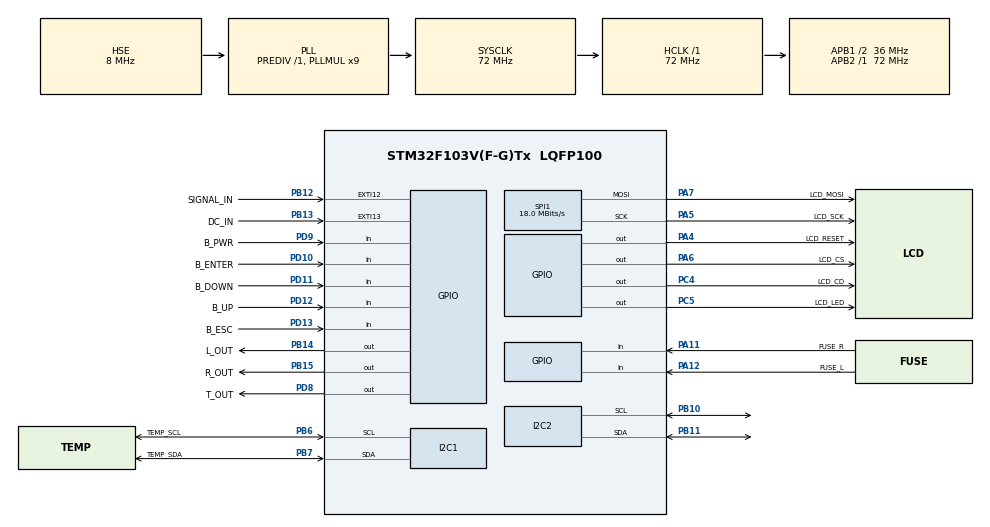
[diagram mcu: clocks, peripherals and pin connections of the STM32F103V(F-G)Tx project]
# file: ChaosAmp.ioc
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Mcu.Family=STM32F1
Mcu.Name=STM32F103V(F-G)Tx
Mcu.Package=LQFP100
NVIC.EXTI15_10_IRQn=true\:0\:0\:false\:false\:true\:true\:true
NVIC.PriorityGroup=NVIC_PRIORITYGROUP_4
OSC_IN.Mode=HSE-External-Oscillator
OSC_IN.Signal=RCC_OSC_IN
OSC_OUT.Mode=HSE-External-Oscillator
OSC_OUT.Signal=RCC_OSC_OUT
PA11.GPIO_Label=FUSE_R
PA11.GPIO_PuPd=GPIO_PULLDOWN
PA11.Signal=GPIO_Input
PA12.GPIO_Label=FUSE_L
PA12.GPIO_PuPd=GPIO_PULLDOWN
PA12.Signal=GPIO_Input
PA13.Mode=Serial_Wire
PA13.Signal=SYS_JTMS-SWDIO
PA14.Mode=Serial_Wire
PA14.Signal=SYS_JTCK-SWCLK
PA4.GPIO_Label=LCD_RESET
PA4.Signal=GPIO_Output
PA5.GPIO_Label=LCD_SCK
PA5.Mode=TX_Only_Simplex_Unidirect_Master
PA5.Signal=SPI1_SCK
PA6.GPIO_Label=LCD_CS
PA6.Signal=GPIO_Output
PA7.GPIO_Label=LCD_MOSI
PA7.Mode=TX_Only_Simplex_Unidirect_Master
PA7.Signal=SPI1_MOSI
PB10.Mode=I2C
PB10.Signal=I2C2_SCL
PB11.Mode=I2C
PB11.Signal=I2C2_SDA
PB12.GPIO_Label=SIGNAL_IN
PB12.GPIO_ModeDefaultEXTI=GPIO_MODE_IT_FALLING
PB12.Signal=GPXTI12
PB13.GPIO_Label=DC_IN
PB13.GPIO_ModeDefaultEXTI=GPIO_MODE_IT_FALLING
PB13.Signal=GPXTI13
PB14.GPIO_Label=L_OUT
PB14.GPIO_PuPd=GPIO_PULLDOWN
PB14.Signal=GPIO_Output
PB15.GPIO_Label=R_OUT
PB15.GPIO_PuPd=GPIO_PULLDOWN
PB15.Signal=GPIO_Output
PB6.GPIO_Label=TEMP_SCL
PB6.Mode=I2C
PB6.Signal=I2C1_SCL
PB7.GPIO_Label=TEMP_SDA
PB7.Mode=I2C
PB7.Signal=I2C1_SDA
PC4.GPIO_Label=LCD_CD
PC4.PinState=GPIO_PIN_RESET
PC4.Signal=GPIO_Output
PC5.GPIO_Label=LCD_LED
PC5.Signal=GPIO_Output
PD10.GPIO_Label=B_ENTER
PD10.GPIO_PuPd=GPIO_PULLUP
PD10.Signal=GPIO_Input
PD11.GPIO_Label=B_DOWN
PD11.GPIO_PuPd=GPIO_PULLUP
PD11.Signal=GPIO_Input
PD12.GPIO_Label=B_UP
PD12.GPIO_PuPd=GPIO_PULLUP
PD12.Signal=GPIO_Input
PD13.GPIO_Label=B_ESC
PD13.GPIO_PuPd=GPIO_PULLUP
PD13.Signal=GPIO_Input
PD8.GPIO_Label=T_OUT
PD8.GPIO_PuPd=GPIO_PULLDOWN
PD8.Signal=GPIO_Output
PD9.GPIO_Label=B_PWR
PD9.GPIO_PuPd=GPIO_PULLUP
PD9.Signal=GPIO_Input
ProjectManager.HeapSize=0x200
ProjectManager.StackSize=0x400
ProjectManager.TargetToolchain=Makefile
RCC.AHBFreq_Value=72000000
RCC.APB1CLKDivider=RCC_HCLK_DIV2
RCC.APB1Freq_Value=36000000
RCC.APB1TimFreq_Value=72000000
RCC.APB2Freq_Value=72000000
RCC.APB2TimFreq_Value=72000000
RCC.HCLKFreq_Value=72000000
RCC.PLLMUL=RCC_PLL_MUL9
RCC.PLLSourceVirtual=RCC_PLLSOURCE_HSE
RCC.SYSCLKFreq_VALUE=72000000
RCC.SYSCLKSource=RCC_SYSCLKSOURCE_PLLCLK
RCC.USBFreq_Value=72000000
SPI1.BaudRatePrescaler=SPI_BAUDRATEPRESCALER_4
SPI1.CalculateBaudRate=18.0 MBits/s
SPI1.Direction=SPI_DIRECTION_2LINES
SPI1.Mode=SPI_MODE_MASTER
SPI1.VirtualType=VM_MASTER
board=custom

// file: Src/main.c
/* USER CODE BEGIN Header */
/**
  ******************************************************************************
  * @file           : main.c
  * @brief          : Main program body
  ******************************************************************************
  * @attention
  *
  * <h2><center>&copy; Copyright (c) 2020 STMicroelectronics.
  * All rights reserved.</center></h2>
  *
  * This software component is licensed by ST under BSD 3-Clause license,
  * the "License"; You may not use this file except in compliance with the
  * License. You may obtain a copy of the License at:
  *                        opensource.org/licenses/BSD-3-Clause
  *
  ******************************************************************************
  */
/* USER CODE END Header */

#include "main.h"

/* USER CODE BEGIN Includes */
#include "AmpIO.h"
/* USER CODE END Includes */

I2C_HandleTypeDef hi2c1;
I2C_HandleTypeDef hi2c2;

SPI_HandleTypeDef hspi1;

void SystemClock_Config(void);
static void MX_GPIO_Init(void);
static void MX_I2C1_Init(void);
static void MX_I2C2_Init(void);
static void MX_SPI1_Init(void);

int main(void)
{

  /* MCU Configuration--------------------------------------------------------*/

  /* Reset of all peripherals, Initializes the Flash interface and the Systick. */
  HAL_Init();

  /* Configure the system clock */
  SystemClock_Config();

  /* Initialize all configured peripherals */
  MX_GPIO_Init();
  MX_I2C1_Init();
  MX_I2C2_Init();
  MX_SPI1_Init();

  /* Infinite loop */
  /* USER CODE BEGIN WHILE */
  while (1)
  {
    AmpIO_loop();
    /* USER CODE END WHILE */

  }
}

void SystemClock_Config(void)
{
  RCC_OscInitTypeDef RCC_OscInitStruct = {0};
  RCC_ClkInitTypeDef RCC_ClkInitStruct = {0};

  /** Initializes the CPU, AHB and APB busses clocks
  */
  RCC_OscInitStruct.OscillatorType = RCC_OSCILLATORTYPE_HSE;
  RCC_OscInitStruct.HSEState = RCC_HSE_ON;
  RCC_OscInitStruct.HSEPredivValue = RCC_HSE_PREDIV_DIV1;
  RCC_OscInitStruct.HSIState = RCC_HSI_ON;
  RCC_OscInitStruct.PLL.PLLState = RCC_PLL_ON;
  RCC_OscInitStruct.PLL.PLLSource = RCC_PLLSOURCE_HSE;
  RCC_OscInitStruct.PLL.PLLMUL = RCC_PLL_MUL9;
  if (HAL_RCC_OscConfig(&RCC_OscInitStruct) != HAL_OK)
  {
    Error_Handler();
  }
  /** Initializes the CPU, AHB and APB busses clocks
  */
  RCC_ClkInitStruct.ClockType = RCC_CLOCKTYPE_HCLK|RCC_CLOCKTYPE_SYSCLK
                              |RCC_CLOCKTYPE_PCLK1|RCC_CLOCKTYPE_PCLK2;
  RCC_ClkInitStruct.SYSCLKSource = RCC_SYSCLKSOURCE_PLLCLK;
  RCC_ClkInitStruct.AHBCLKDivider = RCC_SYSCLK_DIV1;
  RCC_ClkInitStruct.APB1CLKDivider = RCC_HCLK_DIV2;
  RCC_ClkInitStruct.APB2CLKDivider = RCC_HCLK_DIV1;

  if (HAL_RCC_ClockConfig(&RCC_ClkInitStruct, FLASH_LATENCY_2) != HAL_OK)
  {
    Error_Handler();
  }
}

static void MX_I2C1_Init(void)
{

  hi2c1.Instance = I2C1;
  hi2c1.Init.ClockSpeed = 100000;
  hi2c1.Init.DutyCycle = I2C_DUTYCYCLE_2;
  hi2c1.Init.OwnAddress1 = 0;
  hi2c1.Init.AddressingMode = I2C_ADDRESSINGMODE_7BIT;
  hi2c1.Init.DualAddressMode = I2C_DUALADDRESS_DISABLE;
  hi2c1.Init.OwnAddress2 = 0;
  hi2c1.Init.GeneralCallMode = I2C_GENERALCALL_DISABLE;
  hi2c1.Init.NoStretchMode = I2C_NOSTRETCH_DISABLE;
  if (HAL_I2C_Init(&hi2c1) != HAL_OK)
  {
    Error_Handler();
  }

}

static void MX_I2C2_Init(void)
{

  hi2c2.Instance = I2C2;
  hi2c2.Init.ClockSpeed = 100000;
  hi2c2.Init.DutyCycle = I2C_DUTYCYCLE_2;
  hi2c2.Init.OwnAddress1 = 0;
  hi2c2.Init.AddressingMode = I2C_ADDRESSINGMODE_7BIT;
  hi2c2.Init.DualAddressMode = I2C_DUALADDRESS_DISABLE;
  hi2c2.Init.OwnAddress2 = 0;
  hi2c2.Init.GeneralCallMode = I2C_GENERALCALL_DISABLE;
  hi2c2.Init.NoStretchMode = I2C_NOSTRETCH_DISABLE;
  if (HAL_I2C_Init(&hi2c2) != HAL_OK)
  {
    Error_Handler();
  }

}

static void MX_SPI1_Init(void)
{

  /* SPI1 parameter configuration*/
  hspi1.Instance = SPI1;
  hspi1.Init.Mode = SPI_MODE_MASTER;
  hspi1.Init.Direction = SPI_DIRECTION_2LINES;
  hspi1.Init.DataSize = SPI_DATASIZE_8BIT;
  hspi1.Init.CLKPolarity = SPI_POLARITY_LOW;
  hspi1.Init.CLKPhase = SPI_PHASE_1EDGE;
  hspi1.Init.NSS = SPI_NSS_SOFT;
  hspi1.Init.BaudRatePrescaler = SPI_BAUDRATEPRESCALER_4;
  hspi1.Init.FirstBit = SPI_FIRSTBIT_MSB;
  hspi1.Init.TIMode = SPI_TIMODE_DISABLE;
  hspi1.Init.CRCCalculation = SPI_CRCCALCULATION_DISABLE;
  hspi1.Init.CRCPolynomial = 10;
  if (HAL_SPI_Init(&hspi1) != HAL_OK)
  {
    Error_Handler();
  }

}

static void MX_GPIO_Init(void)
{
  GPIO_InitTypeDef GPIO_InitStruct = {0};

  /* GPIO Ports Clock Enable */
  __HAL_RCC_GPIOA_CLK_ENABLE();
  __HAL_RCC_GPIOC_CLK_ENABLE();
  __HAL_RCC_GPIOB_CLK_ENABLE();
  __HAL_RCC_GPIOD_CLK_ENABLE();

  /*Configure GPIO pin Output Level */
  HAL_GPIO_WritePin(GPIOA, LCD_RESET_Pin|LCD_CS_Pin, GPIO_PIN_RESET);

  /*Configure GPIO pin Output Level */
  HAL_GPIO_WritePin(GPIOC, LCD_CD_Pin|LCD_LED_Pin, GPIO_PIN_RESET);

  /*Configure GPIO pin Output Level */
  HAL_GPIO_WritePin(GPIOB, L_OUT_Pin|R_OUT_Pin, GPIO_PIN_RESET);

  /*Configure GPIO pin Output Level */
  HAL_GPIO_WritePin(T_OUT_GPIO_Port, T_OUT_Pin, GPIO_PIN_RESET);

  /*Configure GPIO pins : LCD_RESET_Pin LCD_CS_Pin */
  GPIO_InitStruct.Pin = LCD_RESET_Pin|LCD_CS_Pin;
  GPIO_InitStruct.Mode = GPIO_MODE_OUTPUT_PP;
  GPIO_InitStruct.Pull = GPIO_NOPULL;
  GPIO_InitStruct.Speed = GPIO_SPEED_FREQ_LOW;
  HAL_GPIO_Init(GPIOA, &GPIO_InitStruct);

  /*Configure GPIO pins : LCD_CD_Pin LCD_LED_Pin */
  GPIO_InitStruct.Pin = LCD_CD_Pin|LCD_LED_Pin;
  GPIO_InitStruct.Mode = GPIO_MODE_OUTPUT_PP;
  GPIO_InitStruct.Pull = GPIO_NOPULL;
  GPIO_InitStruct.Speed = GPIO_SPEED_FREQ_LOW;
  HAL_GPIO_Init(GPIOC, &GPIO_InitStruct);

  /*Configure GPIO pins : SIGNAL_IN_Pin DC_IN_Pin */
  GPIO_InitStruct.Pin = SIGNAL_IN_Pin|DC_IN_Pin;
  GPIO_InitStruct.Mode = GPIO_MODE_IT_FALLING;
  GPIO_InitStruct.Pull = GPIO_NOPULL;
  HAL_GPIO_Init(GPIOB, &GPIO_InitStruct);

  /*Configure GPIO pins : L_OUT_Pin R_OUT_Pin */
  GPIO_InitStruct.Pin = L_OUT_Pin|R_OUT_Pin;
  GPIO_InitStruct.Mode = GPIO_MODE_OUTPUT_PP;
  GPIO_InitStruct.Pull = GPIO_PULLDOWN;
  GPIO_InitStruct.Speed = GPIO_SPEED_FREQ_LOW;
  HAL_GPIO_Init(GPIOB, &GPIO_InitStruct);

  /*Configure GPIO pin : T_OUT_Pin */
  GPIO_InitStruct.Pin = T_OUT_Pin;
  GPIO_InitStruct.Mode = GPIO_MODE_OUTPUT_PP;
  GPIO_InitStruct.Pull = GPIO_PULLDOWN;
  GPIO_InitStruct.Speed = GPIO_SPEED_FREQ_LOW;
  HAL_GPIO_Init(T_OUT_GPIO_Port, &GPIO_InitStruct);

  /*Configure GPIO pins : B_PWR_Pin B_ENTER_Pin B_DOWN_Pin B_UP_Pin
                           B_ESC_Pin */
  GPIO_InitStruct.Pin = B_PWR_Pin|B_ENTER_Pin|B_DOWN_Pin|B_UP_Pin
                          |B_ESC_Pin;
  GPIO_InitStruct.Mode = GPIO_MODE_INPUT;
  GPIO_InitStruct.Pull = GPIO_PULLUP;
  HAL_GPIO_Init(GPIOD, &GPIO_InitStruct);

  /*Configure GPIO pins : FUSE_R_Pin FUSE_L_Pin */
  GPIO_InitStruct.Pin = FUSE_R_Pin|FUSE_L_Pin;
  GPIO_InitStruct.Mode = GPIO_MODE_INPUT;
  GPIO_InitStruct.Pull = GPIO_PULLDOWN;
  HAL_GPIO_Init(GPIOA, &GPIO_InitStruct);

  /* EXTI interrupt init*/
  HAL_NVIC_SetPriority(EXTI15_10_IRQn, 0, 0);
  HAL_NVIC_EnableIRQ(EXTI15_10_IRQn);

}

void Error_Handler(void)
{
}

/************************ (C) COPYRIGHT STMicroelectronics *****END OF FILE****/
